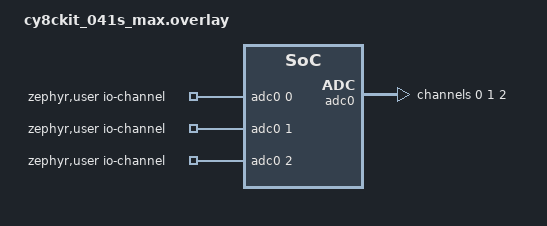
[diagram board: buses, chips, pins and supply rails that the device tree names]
/*
 * Copyright (c) 2025 Infineon Technologies AG,
 * or an affiliate of Infineon Technologies AG.
 *
 * SPDX-License-Identifier: Apache-2.0
 */

/*
 * ADC Channel Configuration for CY8CKIT-041S-MAX
 *
 * Test Setup:
 * - Connect 0.616V test voltage to specified pins
 * - Using internal 1.2V reference
 * - Tests SARMUX (direct GPIO) routing
 *
 * Physical Connections (Arduino headers):
 * - P2.2 (J2-5, A2): Connect to 0.616V (differential V+)
 * - P2.3 (J2-7, A3): Connect to GND (differential V-)
 * - P2.0 (J2-1, A0): Connect to 0.616V (single-ended)
 * - P2.4 (J3-1, A4): Connect to 0.616V (single-ended)
 *
 * Channel	Pin(s)		Routing		Configuration	Test Voltage
 * Channel 0	P2.2, P2.3	SARMUX 2/3	Differential	V+=0.616V, V-=GND
 * Channel 1	P2.0		SARMUX 0	Single-ended	0.616V
 * Channel 2	P2.4		SARMUX 4	Single-ended	0.616V
 */

#include <zephyr/dt-bindings/adc/adc.h>
#include <zephyr/dt-bindings/adc/infineon-sar.h>
#include <zephyr/dt-bindings/pinctrl/ifx_cat1-pinctrl.h>

/ {
	zephyr,user {
		io-channels = <&adc0 0>, <&adc0 1>, <&adc0 2>;
	};
};

&pinctrl {
	p2_2_adc: p2_2_adc {
		pinmux = <DT_CAT1_PINMUX(2, 2, HSIOM_SEL_GPIO)>;
	};

	p2_3_adc: p2_3_adc {
		pinmux = <DT_CAT1_PINMUX(2, 3, HSIOM_SEL_GPIO)>;
	};

	p2_0_adc: p2_0_adc {
		pinmux = <DT_CAT1_PINMUX(2, 0, HSIOM_SEL_GPIO)>;
	};

	p2_4_adc: p2_4_adc {
		pinmux = <DT_CAT1_PINMUX(2, 4, HSIOM_SEL_GPIO)>;
	};
};

&adc0 {
	status = "okay";
	vref-src = "internal";  /* Use internal 1.2V reference */
	pinctrl-0 = <&p2_2_adc &p2_3_adc &p2_0_adc &p2_4_adc>;
	pinctrl-names = "default";
	#address-cells = <1>;
	#size-cells = <0>;

	channel@0 {
		reg = <0>;
		zephyr,gain = "ADC_GAIN_1";
		zephyr,differential;
		zephyr,reference = "ADC_REF_INTERNAL";
		zephyr,vref-mv = <1200>;
		zephyr,input-positive = <CY_SAR_ADDR_SARMUX_2>;  /* SARMUX pin 2 = P2.2 (V+) */
		zephyr,input-negative = <CY_SAR_ADDR_SARMUX_3>;  /* SARMUX pin 3 = P2.3 (V-) */
		zephyr,resolution = <12>;
		zephyr,oversampling = <0>;
		zephyr,acquisition-time = <ADC_ACQ_TIME_DEFAULT>;
	};

	channel@1 {
		reg = <1>;
		zephyr,gain = "ADC_GAIN_1";
		zephyr,reference = "ADC_REF_INTERNAL";
		zephyr,vref-mv = <1200>;
		zephyr,input-positive = <CY_SAR_ADDR_SARMUX_0>;  /* SARMUX pin 0 = P2.0 */
		zephyr,resolution = <12>;
		zephyr,oversampling = <0>;
		zephyr,acquisition-time = <ADC_ACQ_TIME_DEFAULT>;
	};

	channel@2 {
		reg = <2>;
		zephyr,gain = "ADC_GAIN_1";
		zephyr,reference = "ADC_REF_INTERNAL";
		zephyr,vref-mv = <1200>;
		zephyr,input-positive = <CY_SAR_ADDR_SARMUX_4>;  /* SARMUX pin 4 = P2.4 */
		zephyr,resolution = <12>;
		zephyr,oversampling = <0>;
		zephyr,acquisition-time = <ADC_ACQ_TIME_DEFAULT>;
	};
};
